# EHCI register map
Vendor: Texas Instruments
Peripheral module from a debugger description file (folder omap5430_ES2_PUBLIC).
Registers are 32-bit, access per field, reset values left out (the file's numbers can be read two ways) unless marked. A register's access mark holds for its fields unless they carry their own. Offsets are as the file gives them; lines under a group give offsets from that group; [hi:lo] are bit positions; {n}, {i} and the like mark numbered series; 'fields as' and 'values as' point back to an identical list; <NAME> marks a mode.

## EHCI
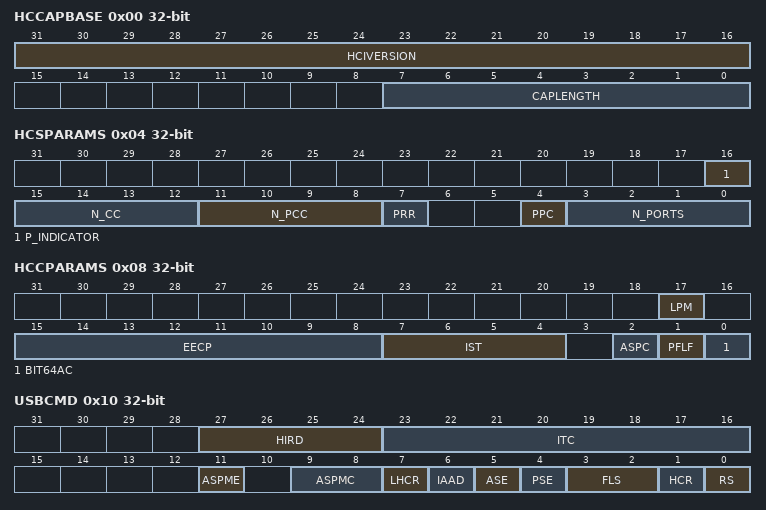
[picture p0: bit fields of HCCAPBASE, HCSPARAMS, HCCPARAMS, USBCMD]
0x00 HCCAPBASE ro — Host controller capability register
  [31:16] HCIVERSION — Interface version number. It contains a BCD encoding of the EHCI revision number supported by this host controller.[7:4] Major revision . [3:0] Minor revision .
  [7:0] CAPLENGTH — Capability register length
0x04 HCSPARAMS ro — Host controller structural parameters
  [16] P_INDICATOR — Port indicator support indicationThis bit indicates whether the ports support port indicator control. .
    1=The port status and control registers include a read/write field for controlling the state of the port indicator
  [15:12] N_CC — Number of companion controllersThis field indicates the number of companion controllers associated with this USB 2.0 host controller. . Others: There are companion USB 1.1 host controller(s). Port-ownership hand-off is supported. High-, full-, and low-speed devices are supported on the host controller root ports. .
    0=There are no companion host controllers. Port-ownership hand-off is not supported. Only high-speed devices are supported on the host controller root ports.
  [11:8] N_PCC — Number of ports per companion controllerThis field indicates the number of ports supported per companion host controller. It is used to indicate the port routing configuration to system software. . For example, if N_PORTS has a value of 6 and N_CC has a value of 2, then N_PCC can have a value of 3. . The convention is that the first N_PCC ports are assumed to be routed to companion controller 1, the next N_PCC ports to companion controller 2, etc. . The number in this field must be consistent with N_PORTS and N_CC. .
  [7] PRR — Port routing rulesThe first N_PCC ports are routed to the lowest-numbered function companion host controller, the next N_PCC ports are routed to the next lowest-function companion controller, and so on. .
  [4] PPC — Port power controlThis field indicates whether the host controller implementation includes port power control. .
    0=The ports do not have port power switches; 1=The_ports_have_port_power_switches
  [3:0] N_PORTS — Number of downstream portsThis field specifies the number of physical downstream ports implemented on this host controller. .
0x08 HCCPARAMS ro — Host controller capability parameters
  [17] LPM — Link power management capability
    0=Link_power_management_not_supported; 1=Link_power_management_supported
  [15:8] EECP — EHCI extended capabilities pointerThis field indicates the existence of a capabilities list. . Others: The offset in PCI configuration space of the first EHCI extended capability. .
    0=No extended capabilities are implemented
  [7:4] IST — Isochronous scheduling thresholdThis field indicates where software can reliably update the isochronous schedule in relation to the current position of the executing host controller. . The host controller can hold one microframe of isochronous data structures before flushing the state. .
  [2] ASPC — Asynchronous schedule park capabilityThe feature can be disabled or enabled and set to a specific level by using the USBHOST.[11]ASPME bit and the USBHOST.[9:8] ASPMC bit field. .
    1=The host controller supports the park feature for high-speed queue heads in the asynchronous schedule
  [1] PFLF — Programmable frame list flag
    0=System software must use a frame list length of 1024 elements with this host controller; 1=USBHOST.[3:2]_FLS_4-K_1 (System software can specify and use a smaller frame list and configure the host controller through the USBHOST.[3:2] FLS bit field. The frame list must always be aligned on a 4-K page boundary.)
  [0] BIT64AC — 64-bit addressing capabilityThis field documents the addressing range capability of this implementation. .
    0=Data structures using 32-bit address memory pointers; 1=Data structures using 64-bit address memory pointers
0x10 USBCMD — USB command
  [27:24] HIRD rw — Host-initiated resume duration.If LPM is enabled, this field is RW; otherwise, it is R. . The minimum for K-state during resume from LPM: . Each increment adds 75 μs. .
    0=50_μs
  [23:16] ITC rw — Interrupt threshold controlThis field is used by the system software to select the maximum rate at which the host controller issues interrupts. The only valid values are defined below. If software writes an invalid value to this register, the results are undefined. . Others: Undefined .
    1=1_microframe; 2=2_microframes; 4=4_microframes; 8=8 microframes (default, equates to 1 ms); 16=16_microframes_(2_ms); 32=32_microframes_(4_ms); 64=64_microframes_(8_ms)
  [11] ASPME rw — Asynchronous schedule park mode enable
    0=Park_mode_is_disabled; 1=Park_mode_is_enabled
  [9:8] ASPMC rw — Asynchronous schedule park mode countIt contains a count of the number of successive transactions the host controller is allowed to execute from a high-speed queue head on the asynchronous schedule before continuing traversal of the asynchronous schedule. . Valid values are 0x1 to 0x3. Software must not write 0 to this bit when park mode enable is 1 because this may result in undefined behavior. .
  [7] LHCR rw — Light host controller resetIt allows the driver to reset the EHCI controller without affecting the state of the ports or the relationship to the companion host controllers. .
    0=LHCR_0_r (Light host controller reset is complete and it is safe for host software to reinitialize the host controller.); 1=LHCR_1_r (Light host controller reset is still ongoing.)
  [6] IAAD rw — Interrupt on async advance doorbellThis bit is used as a doorbell by software to tell the host controller to issue an interrupt the next time it advances asynchronous schedule. . Software must not write 1 to this bit when the asynchronous schedule is disabled. Doing so may yield undefined results. .
    1=Ring_the_doorbell
  [5] ASE rw — Asynchronous schedule enableThis bit controls whether the host controller skips processing the asynchronous schedule. .
    0=Do not process the asynchronous schedule; 1=USBHOST._1 (Use the USBHOST. register to access the asynchronous schedule.)
  [4] PSE rw — Periodic schedule enableThis bit controls whether the host controller skips processing the periodic schedule. .
    0=Do_not_process_the_periodic_schedule; 1=USBHOST._1 (Use the USBHOST. register to access the periodic schedule.)
  [3:2] FLS rw — Frame list sizeThis field specifies the size of the frame list. The size of the frame list controls which bits in the frame index register should be used for the frame list current index. .
    0=1024_elements_(4096_bytes); 1=512_elements_(2048_bytes); 2=256 elements (1024 bytes), for resource-constrained environments
  [1] HCR wo — Host controller resetThis control bit is used by software to reset the host controller. Write . This bit is set to 0 by the host controller when the reset process is complete. .
    1=PCI_1 (Reset the host controller, the PCI configuration registers are not affected by this reset and all operational registers are set to their initial values.)
  [0] RS rw — Run/stop
    1=Run, the host controller proceeds with execution of the schedule. The host controller continues execution as long as this bit is set to 1.; 0=USB_0 (Stop, the host controller completes the current and any actively pipelined transactions on the USB and then halts.)
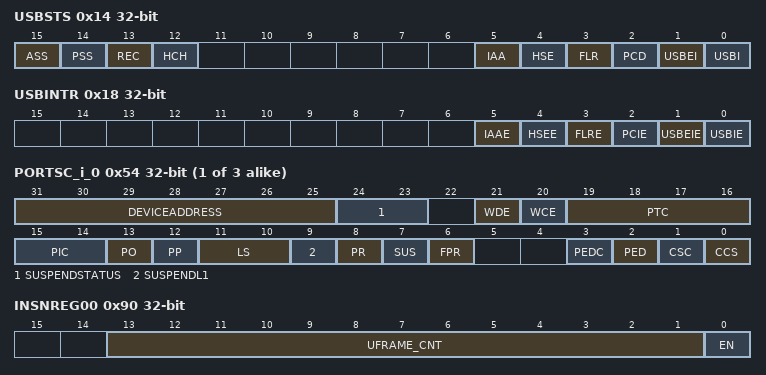
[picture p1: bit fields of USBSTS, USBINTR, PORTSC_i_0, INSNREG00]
0x14 USBSTS — USB status
  [15] ASS ro — Asynchronous schedule statusThe bit reports the current real status of the asynchronous schedule. .
    0=The status of the asynchronous schedule is disabled; 1=The status of the asynchronous schedule is enabled
  [14] PSS ro — Periodic schedule statusThe bit reports the current real status of the periodic schedule. .
    0=The status of the periodic schedule is disabled; 1=The status of the periodic schedule is enabled
  [13] REC ro — ReclamationIt is used to detect an empty asynchronous schedule. .
  [12] HCH ro — Host controller haltedThis bit is a 0 whenever the USBHOST.[0] RS bit is a 1. The host controller sets this bit to 1 after it has stopped executing as a result of the RS bit being set to 0, either by software or by the host controller hardware. .
  [5] IAA rw — Interrupt on async advanceSystem software can force the host controller to issue an interrupt the next time the host controller advances the asynchronous schedule by setting the USBHOST.[6] IAAD bit to 1. This status bit indicates the assertion of that interrupt source. .
  [4] HSE rw — Host system errorThe host controller sets this bit to 1 when a serious error occurs during a host system access involving the host controller module. .
  [3] FLR rw — Frame list rolloverThe host controller sets this bit to 1 when the USBHOST. rolls over from its maximum value to 0. The exact value at which the rollover occurs depends on the frame list size. .
  [2] PCD rw — Port change detectThe host controller sets this bit to 1 when any port for which the USBHOST.[13] PO bit is set to 0 has a change bit transition from 0 to 1 or a USBHOST.[6] FPR bit transition from 0 to 1. . This bit is also set as a result of the USBHOST.[1] CSC bit being set to 1 after system software has relinquished ownership of a connected port by setting the USBHOST.[13] PO bit to 1. .
  [1] USBEI rw — USB error interruptThe host controller sets this bit to 1 when completion of a USB transaction results in an error condition. .
  [0] USBI rw — USB interruptThe host controller sets this bit to 1 on completion of a USB transaction, which results in the retirement of a transfer descriptor that had its IOC bit set. . The host controller also sets this bit to 1 when a short packet is detected (actual number of bytes received was less than the expected number of bytes). .
0x18 USBINTR — USB interrupt enable
  [5] IAAE rw — Interrupt on async advance enable
    1=IAA_IAA_1 (When the[5] IAA bit is 1, the host controller issues an interrupt at the next interrupt threshold. The interrupt is acknowledged by software clearing the [5] IAA bit.)
  [4] HSEE rw — Host system error enable
    1=HSE_HSE_1 (When the[4] HSE bit is 1, the host controller issues an interrupt. The interrupt is acknowledged by software clearing the [4] HSE bit.)
  [3] FLRE rw — Frame list rollover enable
    1=FLR_FLR_1 (When the[3] FLR bit is 1, the host controller issues an interrupt. The interrupt is acknowledged by software clearing the [3] FLR bit.)
  [2] PCIE rw — Port change interrupt enable
    1=PCD_FLR_1 (When the[2] PCD bit is 1, the host controller issues an interrupt. The interrupt is acknowledged by software clearing the [3] FLR bit.)
  [1] USBEIE rw — USB error interrupt enable
    1=USBEI_USBEI_1 (When the[1] USBEI bit is 1, the host controller issues an interrupt at the next interrupt threshold. The interrupt is acknowledged by software clearing the [1] USBEI bit.)
  [0] USBIE rw — USB interrupt enable
    1=USBI_USBI_1 (When the[0] USBI bit is 1, the host controller issues an interrupt at the next interrupt threshold. The interrupt is acknowledged by software clearing the [0] USBI bit.)
0x1C FRINDEX — USB frame index
  [13:0] FI rw — Frame indexThe value in this register is incremented at the end of each time frame. .
0x20 CTRLDSSEGMENT ro — 4G segment selector
  [31:0] CDSS — This 32-bit register corresponds to the most-significant address bits [63:32] for all EHCI data structures.
0x24 PERIODICLISTBASE — Frame list base address
  [31:12] BAL rw — Base address (low)These bits correspond to memory address signals. .
0x28 ASYNCLISTADDR — Next asynchronous list address
  [31:5] LPL rw — Link pointer lowIt contains the address of the next asynchronous queue head to be executed. .
0x50 CONFIGFLAG — Configured flag register
  [0] CF rw — Configure flagThis bit controls the default port-routing control logic. .
    0=Port routing control logic default-routes each port to an implementation-dependent classic host controller; 1=Port routing control logic default-routes all ports to this host controller
{0x54+4i} PORTSC_i_{i} (i=0..2) — Port status/control
  [31:25] DEVICEADDRESS rw — The USB device address for the device attached to and immediately downstream from the associated root port. R/W only if LPM is enabled; otherwise, R.
  [24:23] SUSPENDSTATUS ro — Addition for LPM support.Indicates status of L1 suspend request: .
    0=Success; 1=Not_yet; 2=Not_supported; 3=Time-out/error
  [21] WDE rw — Wake on disconnect enableThis field is 0 if the PP bit is 0. .
    1=WDE_1_w (Enables the port to be sensitive to device disconnects as wake-up events.)
  [20] WCE rw — Wake on connect enableThis field is 0 if the PP bit is 0. .
    1=WCE_1_w (Enables the port to be sensitive to device connects as wake-up events.)
  [19:16] PTC rw — Port test controlThe port is operating in specific test modes as indicated by the specific value. The encoding of the test mode bits are: . Others: Reserved .
    0=Test_mode_not_enabled; 1=Test_J_STATE; 2=Test_K_STATE; 3=Test_SE0_NAK; 4=Test_Packet; 5=Test_FORCE_ENABLE
  [15:14] PIC ro — Port indicator control (not implemented)
  [13] PO rw — Port ownerThis bit unconditionally goes to 0x0 when the USBHOST.[0] CF bit makes a transition from 0 to 1. This bit unconditionally goes to 0 whenever the USBHOST.[0] CF bit is 0. .
    1=A_1 (A companion host controller owns and controls the port.)
  [12] PP rw — Port powerThe function of this bit depends on the value of the USBHOST.[4] PPC bit. The behavior is as follows: . PPC PP Operation . 0x0 0x0 Forbidden . 0x0 0x1 Host controller does not have port power. control switches. Each port is hardwired to power. . 0x1 0x0 Host controller has port power control switches. Current switch state is off. . 0x1 0x1 Host controller has port power control switches. Current switch state is on. . When an overcurrent condition is detected on a powered port and the USBHOST.[4] PPC bit is a 1, the PP bit in each affected port may be transitioned by the host controller from 1 to 0. .
  [11:10] LS ro — Line statusThese bits reflect the current logical levels of the D+ (bit 11) and D– (bit 10) signal lines. This field is valid only when the port enable bit is 0 and the current connect status bit is set to 1. The encoding of the bits is: . Bits[11:10] USB State Interpretation . 0x0 SE0 Not low-speed device, perform EHCI reset. . 0x2 J-state Not low-speed device, perform EHCI reset. . 0x1 K-state Low-speed device, release ownership of port. . 0x3 Undefined Not low-speed device, perform EHCI reset. .
  [9] SUSPENDL1 rw — When this bit is set to 1, an LPM token is generated.
    0=Suspend_using_L2; 1=Suspend_using_L1_(LPM)
  [8] PR rw — Port resetThis field is 0 if the PP bit is 0. . Write 0x1 when at 0x0: The bus reset sequence is started. .
    0=Port_is_not_in_reset; 1=Port_is_in_reset; 0=Terminate_the_bus_reset_sequence
  [7] SUS rw — SuspendThis field is 0 if the PP bit is 0. . 0x0 when PED = 0x1: Port enabled . 0x1 when PED = 0x1: Port in suspend state .
    0=Port_disabled
  [6] FPR rw — Force port resumeThis field is 0 if the PP bit is 0. .
    0=No resume (K-state) detected/driven on port; 1=Resume_detected/driven_on_port
  [3] PEDC rw — Port enabled/disabled changeThis field is 0 if the PP bit is 0. .
    0=No_change; 1=PEDC_1_r (Port enabled/disabled status has changed.); 1=Clears_this_bit_to_0
  [2] PED rw — Port enabled/disabledSoftware cannot enable a port by setting this bit to 1. The host controller only sets this to 1 when the reset sequence determines that the attached device is a high-speed device. . Ports can be disabled by either a fault condition (disconnect event or other fault condition) or by host software. . This field is 0 if the PP bit is 0. .
    0=Disable; 1=Enable
  [1] CSC rw — Connect status changeIndicates a change has occurred in the port CCS bit. . This field is 0 if the PP bit is 0. .
    0=No_change; 1=Change_in_current_connect_status; 1=Clears_this_bit_to_0
  [0] CCS ro — Current connect statusThis value reflects the current state of the port, and may not correspond directly to the event that caused the CSC bit to be set. . This field is 0 if the PP bit is 0. .
    0=No_device_is_present; 1=Device_is_present_on_port
0x90 INSNREG00 — Implementation-specific register 0
  [13:1] UFRAME_CNT rw — 1-microframe length value, to reduce simulation time. SIMULATIONS ONLY, NOT AN ACTUAL REGISTER.
  [0] EN rw — Enable of this register
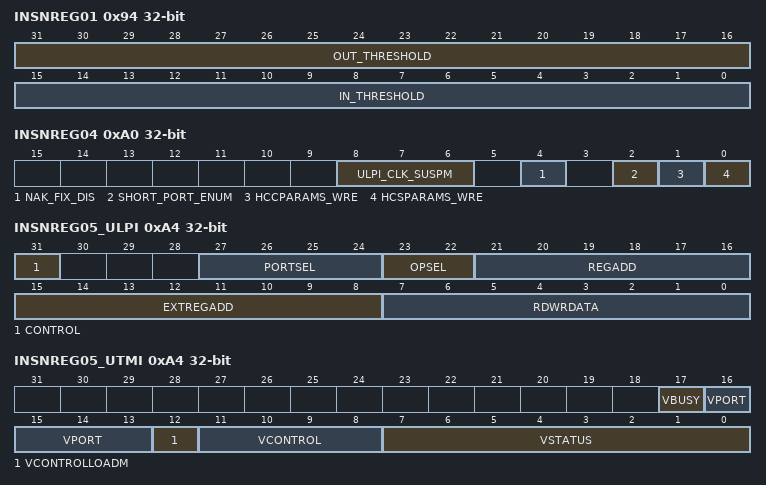
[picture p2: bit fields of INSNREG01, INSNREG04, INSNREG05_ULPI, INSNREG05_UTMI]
0x94 INSNREG01 rw — Implementation-specific register 1
  [31:16] OUT_THRESHOLD — Programmable output packet buffer threshold, in 32-bit words
  [15:0] IN_THRESHOLD — Programmable input packet buffer threshold, in 32-bit words
0x98 INSNREG02 — Implementation-specific register 2
  [11:0] BUF_DEPTH rw — Programmable packet buffer depth, in 32-bit words
0x9C INSNREG03 — Implementation-specific register 3
  [0] BRK_MEM_TRSF rw — Break memory transfer, in conjunction withINSNREG01
    0=Dis (Disabled); 1=En (Enabled)
0xA0 INSNREG04 — Implementation-specific register 4
  [8:6] ULPI_CLK_SUSPM rw — Software control for ULPI FS/LS serial mode clock suspendm feature. By default this feature is disabled. One bit per port. Example: 3'b001, the feature enabled for Port 3 and Port 2 and disabled for Port 1.
  [4] NAK_FIX_DIS rw — Disable NAK fix (don't touch)
  [2] SHORT_PORT_ENUM rw — Scale down port enumeration time (debug)
  [1] HCCPARAMS_WRE rw — Make read-onlyHCCPARAMS register writable (debug)
  [0] HCSPARAMS_WRE rw — Make read-onlyHCSPARAMS register writable (debug)
0xA4 INSNREG05_ULPI — Implementation-specific register 5. Register functionality for ULPI mode.
  [31] CONTROL rw — Control/status of the ULPI register access
    0=busy (No effect); 0=busy (ULPI access done); 1=done (Start ULPI access)
  [27:24] PORTSEL rw
    1=P1 (Port 1 selected for register access); 2=P2 (Port 2 selected for register access)
  [23:22] OPSEL rw
    2=Wr (Register access is write.); 3=Rd (Register access is read.)
  [21:16] REGADD rw — ULPI direct register address, for any value different than 0x2F.
    47=ext (Triggers an extended address)
  [15:8] EXTREGADD rw — Address for extended register accesses. Don't care for direct accesses.
  [7:0] RDWRDATA rw — Read/write data of (resp. read/write) register access
0xA4 INSNREG05_UTMI — Implementation-specific register 5. Register functionality for UTMI mode.
  [17] VBUSY ro
    0=done (Vendor interface is done/inactive); 1=busy (Vendor interface is busy)
  [16:13] VPORT rw — Vendor interface port selection .
    1=P1 (Port 1 vendor interface selected); 2=P2 (Port 2 vendor interface selected)
  [12] VCONTROLLOADM rw — UTMI VcontrolLoadM output (active-low)
    0=Load Vcontrol value into PHY; 1=noaction
  [11:8] VCONTROL rw — UTMI Vcontrol output, to be loaded into the PHY
  [7:0] VSTATUS ro — UTMI Vstatus input image, from PHY
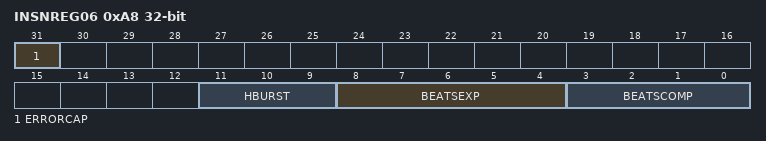
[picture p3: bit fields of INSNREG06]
0xA8 INSNREG06 — AHB error status
  [31] ERRORCAP rw — Indicator that an AHB error was encountered and values were captured
    0=noerror; 0=noerror (Clear pending error); 1=error (No action); 1=Error pending
  [11:9] HBURST ro — HBURST Value of the control phase at which the AHB error occurred
  [8:4] BEATSEXP ro — Number of beats expected in the burst at which the AHB error occurred. Valid values are 0 to 16.
  [3:0] BEATSCOMP ro — Number of successfully completed beats in the current burst before the AHB error occurred
0xAC INSNREG07 ro — AHB master error address
  [31:0] MASTERERRADD
0xB0 INSNREG08
  [15:0] NEWBITFIELD1 rw
